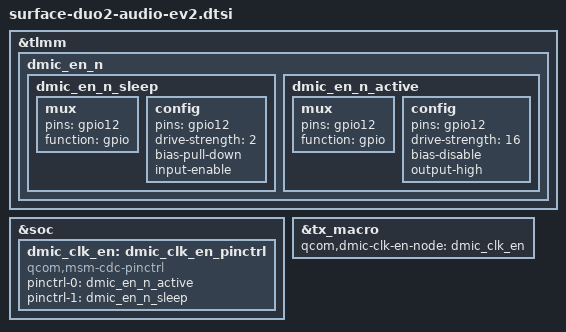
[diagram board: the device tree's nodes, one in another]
/*
 * Copyright (c) 2020 Microsoft Corporation
 *
 * This program is free software; you can redistribute it and/or modify it
 * under the terms of the GNU General Public License version 2 as published by
 * the Free Software Foundation.
 */

/*
 * Audio overlay for EV2
 */

&tlmm {
        /* DMIC enable pins */
        dmic_en_n {
                dmic_en_n_sleep: dmic_en_n_sleep {
                        mux {
                                pins = "gpio12";
                                function = "gpio";
                        };

                        config {
                                pins = "gpio12";
                                drive-strength = <2>;   /* 2 mA */
                                bias-pull-down;
                                input-enable;
                        };
                };
                dmic_en_n_active: dmic_en_n_active {
                        mux {
                                pins = "gpio12";
                                function = "gpio";
                        };

                        config {
                                pins = "gpio12";
                                drive-strength = <16>;   /* 16 mA */
                                bias-disable;
                                output-high;
                        };
                };
        };
};

&soc {
        dmic_clk_en: dmic_clk_en_pinctrl {
                compatible = "qcom,msm-cdc-pinctrl";
                pinctrl-names = "aud_active", "aud_sleep";
                pinctrl-0 = <&dmic_en_n_active>;
                pinctrl-1 = <&dmic_en_n_sleep>;
        };
};

&tx_macro {
       qcom,dmic-clk-en-node = <&dmic_clk_en>;
};
